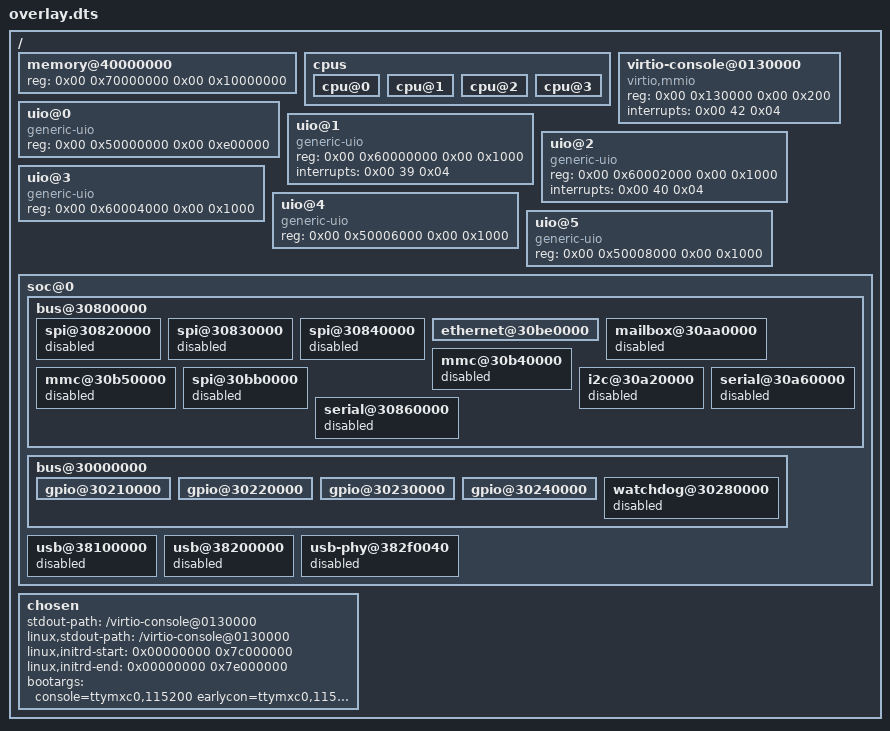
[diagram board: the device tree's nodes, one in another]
/*
 * Copyright 2024, UNSW
 *
 * SPDX-License-Identifier: BSD-2-Clause
 */
/ {
    memory@40000000 {
        device_type = "memory";
        reg = <0x00 0x70000000 0x00 0x10000000>;
    };

    cpus {
        cpu@0 {
            /delete-property/ cpu-idle-states;
        };
        cpu@1 {
            /delete-property/ cpu-idle-states;
        };
        cpu@2 {
            /delete-property/ cpu-idle-states;
        };
        cpu@3 {
            /delete-property/ cpu-idle-states;
        };
    };

    virtio-console@0130000 {
        compatible = "virtio,mmio";
        reg = <0x00 0x130000 0x00 0x200>;
        interrupts = <0x00 42 0x04>;
        // IRQ = 74
    };

    uio@0 {
        compatible = "generic-uio";
        reg = <
            0x00 0x50000000 0x00 0xe00000

            // sDDF control and data queues
            // 0x40000000 is eth_rx_free_drv
            // 0x40200000 is eth_rx_active_drv
            // 0x40400000 is eth_tx_free_drv
            // 0x40600000 is eth_tx_active_drv
            // 0x40800000 is rx data region
            // 0x40a00000 is tx cli0 data region
            // 0x40c00000 is tx cli1 data region
        >;
    };

    uio@1 {
        compatible = "generic-uio\0uio";
        reg = <
            // Hypervisor -> VM interrupt for TX path. VM will poll on this UIO FD,
            // a vIRQ inject from the hypervisor trigger an event in the net UIO driver.
            0x00 0x60000000 0x00 0x1000
        >;
        interrupts = <0x00 39 0x04>;
        // IRQ = 71
    };

    uio@2 {
        compatible = "generic-uio\0uio";
        reg = <
            // Same idea as above but for RX
            0x00 0x60002000 0x00 0x1000
        >;
        interrupts = <0x00 40 0x04>;
        // IRQ = 72
    };

    uio@3 {
        compatible = "generic-uio\0uio";
        reg = <
            // Small memory region that is shared between the guest and VMM, for the VMM to ferry
            // the physical addresses of `eth_tx_buffer_data_region_micropython` and
            // `eth_rx_buffer_data_region` to the guest because the addr in buffer queues is relative to
            // physical addr for DMA.
            0x00 0x60004000 0x00 0x1000
        >;
    };

    uio@4 {
        compatible = "generic-uio\0uio";
        reg = <
            // VM -> Hypervisor interrupt for TX path. This physaddr remain unmapped in guest
            // Guest writes to this address when it want to notify the VMM.
            0x00 0x50006000 0x00 0x1000
        >;
    };

    uio@5 {
        compatible = "generic-uio\0uio";
        reg = <
            // Same idea as above but for RX
            0x00 0x50008000 0x00 0x1000
        >;
    };

    soc@0 {
        bus@30800000 {
            spi@30820000 {
                status = "disabled";
            };

            spi@30830000 {
                status = "disabled";
            };

            spi@30840000 {
                status = "disabled";
            };

            ethernet@30be0000 {
                status = "okay";
            };

            mailbox@30aa0000 {
                status = "disabled";
            };

            mmc@30b40000 {
                status = "disabled";
            };

            mmc@30b50000 {
                status = "disabled";
            };

            spi@30bb0000 {
                status = "disabled";
            };

            i2c@30a20000 {
                status = "disabled";
            };

	     	serial@30a60000 {
                status = "disabled";
            };

            serial@30860000 {
                status = "disabled";
            };
        };

        bus@30000000 {
            gpio@30210000 {
                status = "okay";
            };

            gpio@30220000 {
                status = "okay";
            };

            gpio@30230000 {
                status = "okay";
            };

            gpio@30240000 {
                status = "okay";
            };

            watchdog@30280000 {
                status = "disabled";
            };

        };

        usb@38100000 {
            status = "disabled";
        };

        usb@38200000 {
            status = "disabled";
        };

        usb-phy@382f0040 {
            status = "disabled";
        };
    };

    chosen {
        stdout-path = "/virtio-console@0130000";
        linux,stdout-path = "/virtio-console@0130000";
        linux,initrd-start = <0x00000000 0x7c000000>;
        linux,initrd-end = <0x00000000 0x7e000000>;
        bootargs = "console=ttymxc0,115200 earlycon=ttymxc0,115200 nosmp rw loglevel=8 debug initcall_blacklist=imx8_soc_init pci=nomsi earlyprintk=serial maxcpus=1 uio_pdrv_genirq.of_id=generic-uio";
    };
};
